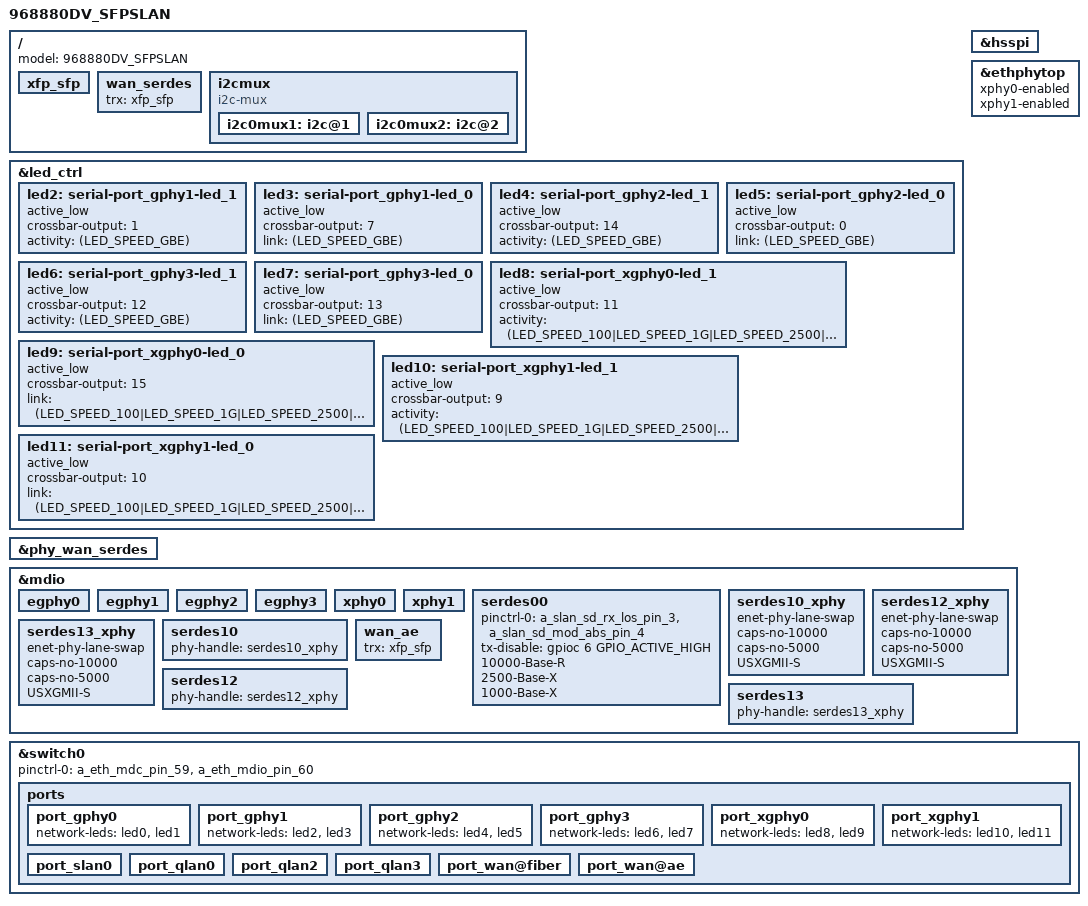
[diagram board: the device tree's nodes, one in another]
#include "inc/968880DV_common.dtsi"

/ {
        model = "968880DV_SFPSLAN";

        xfp_sfp: xfp_sfp {
                status = "okay";
        };

        wan_serdes {
                trx = <&xfp_sfp>;
        };

        i2cmux {
                status = "okay";

                i2c0mux1: i2c@1 {
                    status = "okay";
                };

                i2c0mux2: i2c@2 {
                    status = "okay";
                };
        };
};

&led_ctrl {
    led2: serial-port_gphy1-led_1 {
        active_low;
        crossbar-output = <1>;
        activity = <(LED_SPEED_GBE)>;
        status = "okay";
    };

    led3: serial-port_gphy1-led_0 {
        active_low;
        crossbar-output = <7>;
        link = <(LED_SPEED_GBE)>;
        status = "okay";
    };

    led4: serial-port_gphy2-led_1 {
        active_low;
        crossbar-output = <14>;
        activity = <(LED_SPEED_GBE)>;
        status = "okay";
    };

    led5: serial-port_gphy2-led_0 {
        active_low;
        crossbar-output = <0>;
        link = <(LED_SPEED_GBE)>;
        status = "okay";
    };

    led6: serial-port_gphy3-led_1 {
        active_low;
        crossbar-output = <12>;
        activity = <(LED_SPEED_GBE)>;
        status = "okay";
    };

    led7: serial-port_gphy3-led_0 {
        active_low;
        crossbar-output = <13>;
        link = <(LED_SPEED_GBE)>;
        status = "okay";
    };

    led8: serial-port_xgphy0-led_1 {
        active_low;
        crossbar-output = <11>;
        activity = <(LED_SPEED_100|LED_SPEED_1G|LED_SPEED_2500|LED_SPEED_10G)>;
        status = "okay";
    };

    led9: serial-port_xgphy0-led_0 {
        active_low;
        crossbar-output = <15>;
        link = <(LED_SPEED_100|LED_SPEED_1G|LED_SPEED_2500|LED_SPEED_10G)>;
        status = "okay";
    };

    led10: serial-port_xgphy1-led_1 {
        active_low;
        crossbar-output = <9>;
        activity = <(LED_SPEED_100|LED_SPEED_1G|LED_SPEED_2500|LED_SPEED_10G)>;
        status = "okay";
    };

    led11: serial-port_xgphy1-led_0 {
        active_low;
        crossbar-output = <10>;
        link = <(LED_SPEED_100|LED_SPEED_1G|LED_SPEED_2500|LED_SPEED_10G)>;
        status = "okay";
    };
};

&phy_wan_serdes {
    status = "okay";
};

&hsspi {
    status = "okay";
};

&ethphytop {
    status = "okay";
    xphy0-enabled;
    xphy1-enabled;
};

&mdio {
    egphy0 {
        status = "okay";
    };
    egphy1 {
        status = "okay";
    };
    egphy2 {
        status = "okay";
    };
    egphy3 {
        status = "okay";
    };
    xphy0 {
        status = "okay";
    };
    xphy1 {
        status = "okay";
    };
    serdes00 {
        pinctrl-names = "default";
        pinctrl-0 = <&a_slan_sd_rx_los_pin_3 &a_slan_sd_mod_abs_pin_4>;
        tx-disable = <&gpioc 6 GPIO_ACTIVE_HIGH>;
        10000-Base-R;
        2500-Base-X;
        1000-Base-X;
        status = "okay";
    };
    serdes10_xphy {
        enet-phy-lane-swap;
        caps-no-10000;
        caps-no-5000;
        USXGMII-S;
        status = "okay";
    };
    serdes12_xphy {
        enet-phy-lane-swap;
        caps-no-10000;
        caps-no-5000;
        USXGMII-S;
        status = "okay";
    };
    serdes13_xphy {
        enet-phy-lane-swap;
        caps-no-10000;
        caps-no-5000;
        USXGMII-S;
        status = "okay";
    };
    serdes10 {
        phy-handle = <&serdes10_xphy>;
        status = "okay";
    };
    serdes12 {
        phy-handle = <&serdes12_xphy>;
        status = "okay";
    };
    serdes13 {
        phy-handle = <&serdes13_xphy>;
        status = "okay";
    };
    wan_ae {
        trx = <&xfp_sfp>;
        status = "okay";
    };
};

&switch0 {
    pinctrl-names = "default";
    pinctrl-0 = <&a_eth_mdc_pin_59 &a_eth_mdio_pin_60>;

    ports {
        port_gphy0 {
            status = "okay";
            network-leds = <&led0 &led1>;
        };
        port_gphy1 {
            network-leds = <&led2 &led3>;
            status = "okay";
        };
        port_gphy2 {
            network-leds = <&led4 &led5>;
            status = "okay";
        };
        port_gphy3 {
            network-leds = <&led6 &led7>;
            status = "okay";
        };
        port_xgphy0 {
            network-leds = <&led8 &led9>;
            status = "okay";
        };
        port_xgphy1 {
            network-leds = <&led10 &led11>;
            status = "okay";
        };
        port_slan0 {
            status = "okay";
        };
        port_qlan0 {
            status = "okay";
        };
        port_qlan2 {
            status = "okay";
        };
        port_qlan3 {
            status = "okay";
        };
        port_wan@fiber {
            status = "okay";
        };
        port_wan@ae {
            status = "okay";
        };
    };
};
